# NPCX498S register map
File version: 1.0
Registers are 8-bit, read-write, reset 0x0 unless marked. A register's access mark holds for its fields unless they carry their own. Offsets are from the block's base; [hi:lo] are bit positions; {n}, {i} and the like mark numbered series; 'fields as' and 'values as' point back to an identical list.

## GPIO0
Base 0x40081000
Same registers: GPIO{n} {0x40081000+0x2000*n} (n=1..9), GPIOA 0x40095000, GPIOB 0x40097000, GPIOC 0x40099000, GPIOD 0x4009B000, GPIOE 0x4009D000, GPIOF 0x4009F000
0x00 PxDOUT — Port GPIOx Data Out Register (PxDOUT)
0x01 PxDIN — Port GPIOx Data In Register (PxDIN)
0x02 PxDIR — Port GPIOx Direction Register (PxDIR)
0x03 PxPULL — Port GPIOx Pull-Up or Pull-Down Enable Register (PxPULL)
0x04 PxPUD — Port GPIOx Pull-Up/Down Selection Register (PxPUD)
0x05 PxENVDD — Port GPIOx Drive Enable by VDD Present Register (PxENVDD)
0x06 PxOTYPE — Port GPIOx Output Type Register (PxOTYPE)
0x07 PxLOCK_CTL — Port GPIOx Lock Control Register (PxLOCK_CTL)

## HFCG
Base 0x400B5000
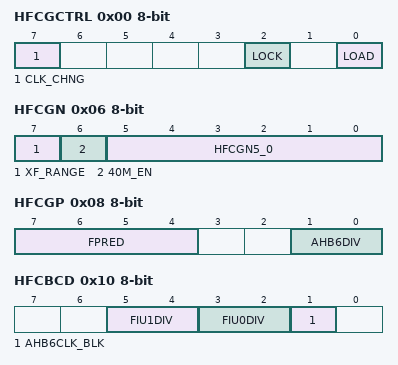
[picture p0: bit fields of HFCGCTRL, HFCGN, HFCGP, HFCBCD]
0x00 HFCGCTRL — HFCG Control Register (HFCGCTRL)
  [7] CLK_CHNG — Clock Changing
  [2] LOCK — Disable Writing to all HFCG registers
  [0] LOAD — Load M and N Values
0x02 HFCGML — HFCG M Low Value Register (HFCGML)
0x04 HFCGMH — HFCG M High Value Register (HFCGMH)
0x06 HFCGN — HFCG N Value Register (HFCGN)
  [7] XF_RANGE — Extended Frequency Range
  [6] 40M_EN — 40 MHz Enable
  [5:0] HFCGN5_0 — N Value Bits 5-0
0x08 HFCGP — HFCG Prescaler Register (HFCGP)
  [7:4] FPRED — Core Clock Prescaler Divider Value
  [1:0] AHB6DIV — AHB6 Clock Divider
0x10 HFCBCD — HFCG Bus Clock Dividers Register (HFCBCD)
  [5:4] FIU1DIV — FIU1 Clock Divider
  [3:2] FIU0DIV — FIU0 Clock Divider
  [1] AHB6CLK_BLK — AHB6 Clock Block
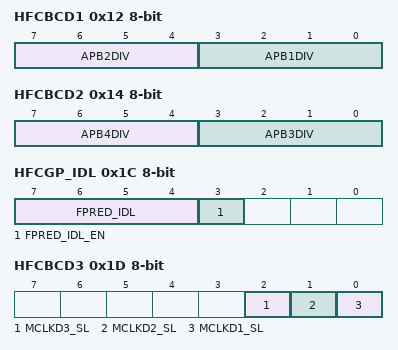
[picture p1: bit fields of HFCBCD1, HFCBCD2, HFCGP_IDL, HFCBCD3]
0x12 HFCBCD1 — HFCG Bus Clock Dividers 1 Register (HFCBCD1)
  [7:4] APB2DIV — APB2 Clock Divider
  [3:0] APB1DIV — APB1 Clock Divider
0x14 HFCBCD2 — HFCG Bus Clock Dividers 2 Register (HFCBCD2)
  [7:4] APB4DIV — APB4 Clock Divider
  [3:0] APB3DIV — APB3 Clock Divider
0x1C HFCGP_IDL — HFCG Prescaler in Idle Register (HFCGP_IDL)
  [7:4] FPRED_IDL — Core Clock Prescaler Divider in Idle Value
  [3] FPRED_IDL_EN — Core Clock Prescaler Divider in Idle Value Enable
0x1D HFCBCD3 — HFCG Bus Clock Dividers 3 Register (HFCBCD3)
  [2] MCLKD3_SL — MCLK Division for I3CI3 Select
  [1] MCLKD2_SL — MCLK Division for I3CI2 Select
  [0] MCLKD1_SL — MCLK Division for I3CI1 Select

## I3C1
Base 0x400F0000
Same registers: I3C2 0x400F2000, I3C3 0x400F4000
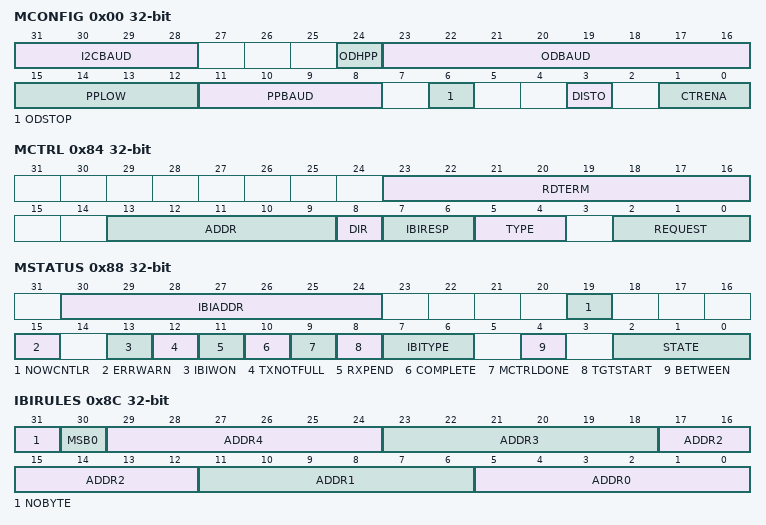
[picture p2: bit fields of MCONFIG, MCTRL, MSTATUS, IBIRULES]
0x00 MCONFIG 32-bit (reset mask 0xFF) — Controller Configuration
  [31:28] I2CBAUD — I2C Baud Rate
  [24] ODHPP — Open-Drain High Period
  [23:16] ODBAUD — Open-Drain Baud Rate
  [15:12] PPLOW — Push-Pull Low Period
  [11:8] PPBAUD — Push-Pull Baud Rate
  [6] ODSTOP — Open-Drain Stop
  [3] DISTO — Disable Timeout Error
  [1:0] CTRENA — Controller Device Enable.
0x84 MCTRL 32-bit (reset mask 0xFF) — Controller Control Register
  [23:16] RDTERM — Read Termination Counter
  [13:9] ADDR — Address
  [8] DIR — Transfer Direction
  [7:6] IBIRESP — IBI Response
  [5:4] TYPE — Operation Type
  [2:0] REQUEST — Bus Operation Request
0x88 MSTATUS 32-bit (reset mask 0xFF) — Controller Status Register
  [30:24] IBIADDR — IBI Address
  [19] NOWCNTLR — I3CI Now Bus Controller
  [15] ERRWARN — Error/Warning
  [13] IBIWON — IBI Arbitration Won
  [12] TXNOTFULL — Transmit Buffer Not Full
  [11] RXPEND — Receive Buffer Pending
  [10] COMPLETE — Message Completed
  [9] MCTRLDONE
  [8] TGTSTART — Target START Detected
  [7:6] IBITYPE
  [4] BETWEEN — Between Messages
  [2:0] STATE — Current Working State
0x8C IBIRULES 32-bit (reset mask 0xFF) — IBI Registry and Rules Register
  [31] NOBYTE — No Mandatory Byte
  [30] MSB0 — MSb is 0
  [6n+5:6n] ADDR{n} (n=0..4) — Target {n} Dynamic Address
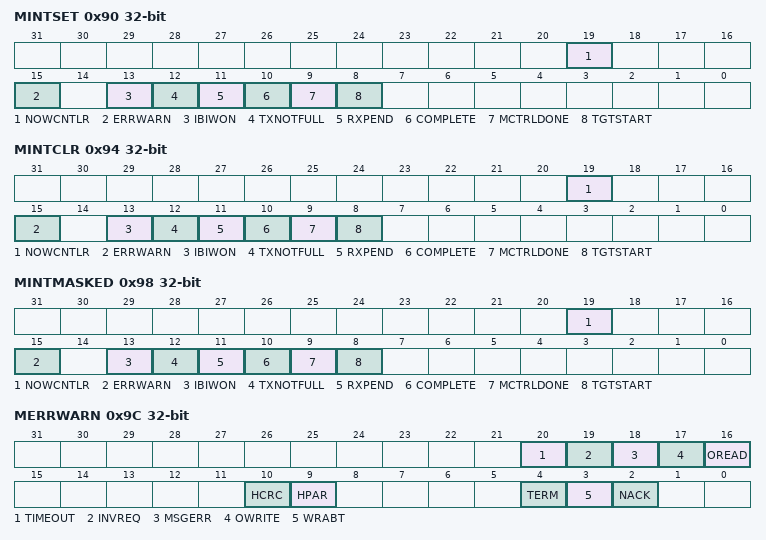
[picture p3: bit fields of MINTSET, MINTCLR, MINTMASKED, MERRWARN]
0x90 MINTSET 32-bit (reset mask 0xFF) — Controller Interrupt Enable Set Register
  [19] NOWCNTLR — I3CI Now Bus Controller
  [15] ERRWARN — Error/Warning
  [13] IBIWON — IBI Arbitration Won
  [12] TXNOTFULL — Transmit Buffer Not Full
  [11] RXPEND — Receive Buffer Pending
  [10] COMPLETE — Message Completed
  [9] MCTRLDONE
  [8] TGTSTART — Target START Detected
0x94 MINTCLR 32-bit (reset mask 0xFF) — Controller Interrupt Enable Clear Register
  fields as MINTSET
0x98 MINTMASKED 32-bit (reset mask 0xFF) — Controller Interrupt Masked Register
  fields as MINTSET
0x9C MERRWARN 32-bit (reset mask 0xFF) — Controller Error and Warning Register
  [20] TIMEOUT
  [19] INVREQ
  [18] MSGERR
  [17] OWRITE
  [16] OREAD
  [10] HCRC — HDR-DDR CRC Error
  [9] HPAR — HDR Parity Error
  [4] TERM — Terminated
  [3] WRABT — Write Aborted
  [2] NACK — Address NACKed
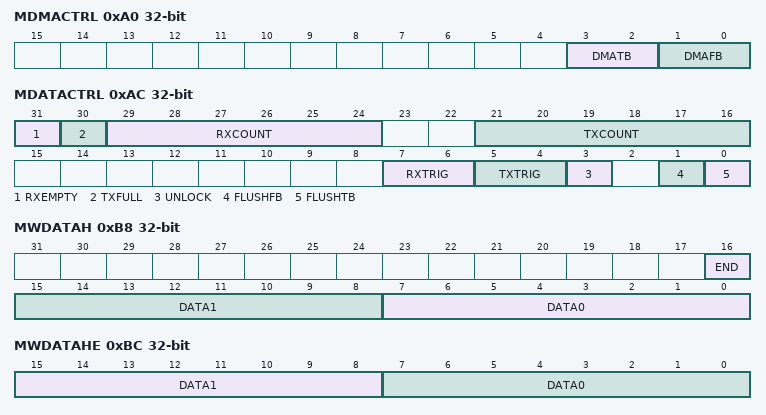
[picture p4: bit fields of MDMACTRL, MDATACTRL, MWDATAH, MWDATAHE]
0xA0 MDMACTRL 32-bit — Controller DMA Control Register
  [3:2] DMATB — DMA to Bus
  [1:0] DMAFB — DMA from Bus
0xAC MDATACTRL 32-bit (reset mask 0xFF) — Controller Data Control Register
  [31] RXEMPTY — Receive Buffer Empty
  [30] TXFULL — Transmit Buffer Full
  [29:24] RXCOUNT — Receive Count
  [21:16] TXCOUNT — Transmit Count
  [7:6] RXTRIG — Receive Trigger
  [5:4] TXTRIG — Transmit Trigger
  [3] UNLOCK
  [1] FLUSHFB — Flush From-Bus Buffer
  [0] FLUSHTB — Flush To-Bus Buffer
0xB4 MWDATABE 32-bit — Controller Write Byte Data as End Register
  [7:0] DATA — Data Byte
0xB8 MWDATAH 32-bit (reset mask 0xFF) — Controller Write Half-Word Data Register
  [16] END — End of Data
  [15:8] DATA1 — Second Data Byte
  [7:0] DATA0 — First Data Byte
0xBC MWDATAHE 32-bit (reset mask 0xFF) — Controller Write Half-Word Data as End Register
  [15:8] DATA1 — Second Data Byte
  [7:0] DATA0 — First Data Byte
0xC0 MRDATAB 32-bit — Controller Read Byte Data Register
  [7:0] DATA — Data Byte
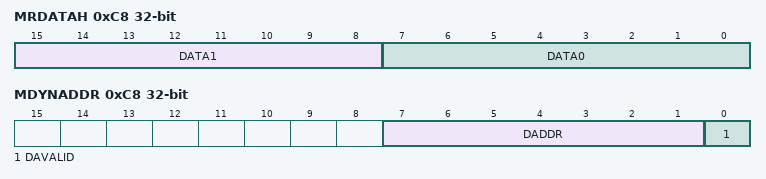
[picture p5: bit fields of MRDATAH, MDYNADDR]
0xC8 MRDATAH 32-bit (reset mask 0xFF) — Controller Read Half-Word Data Register
  [15:8] DATA1 — Second Data Byte
  [7:0] DATA0 — First Data Byte
0xC8 MDYNADDR 32-bit — Controller Dynamic Address Register
  [7:1] DADDR — Dynamic Address
  [0] DAVALID — Address Valid
0xD8 MWMSG_DDR 32-bit (reset mask 0xFF) — Start or Continue DDR Message Register
  [15:0] DATA — Data for HDR-DDR Writes
0xDC MRMSG_DDR 32-bit (reset mask 0xFF) — Read DDR Message Register
  [15:0] DATA — Read Data
